AUTOSAR XML (schema 00049)
standard types defined: uint8
package /Observation2SWC_Config/Types/ImplementationDataTypes
  impl type TYP_ExchangedData: category=VALUE, base-type=uint8
package /Observation2SWC_Config/Types/SwAddrMethods
  sw addr method CODE: section-type=CODE
  sw addr method CONST: section-type=CONST
  sw addr method VAR: section-type=VAR
package /Observation2SWC_Config/Types/Units
  unit NoUnit: factor-si-to-unit=1, offset-si-to-unit=0
package /Observation2SWC_Config/Interfaces
  sender receiver interface IF_ExchangedData
    data DE_ExchangedData: category=VALUE, sw-calibration-access=READ-ONLY, type=TYP_ExchangedData
    data DE_ExchangedEvent: category=VALUE, sw-calibration-access=READ-ONLY, sw-impl-policy=QUEUED, type=TYP_ExchangedData
package /Observation2SWC_Config/SWCs
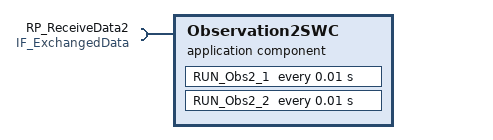
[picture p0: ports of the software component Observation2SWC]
  application sw component type Observation2SWC
    require port RP_ReceiveData2: nonqueued-receiver-com-spec{data-element=DE_ExchangedData, init-value=0}, required-interface=IF_ExchangedData
    behavior Observation2SWC_IB: handle-termination-and-restart=NO-SUPPORT
      timing event Ev_Ti_RUN_Obs2_1: start-on-event=RUN_Obs2_1, period=0.01
      timing event Ev_Ti_RUN_Obs2_2: start-on-event=RUN_Obs2_2, period=0.01
      runnable RUN_Obs2_1
        data-read-access:
          access VDP_ImplRead2_1: accessed-variable=RP_ReceiveData2.DE_ExchangedData
      runnable RUN_Obs2_2
        data-read-access:
          access VDP_ImplRead2_2: accessed-variable=RP_ReceiveData2.DE_ExchangedData
